# ATmega406 device description
Architecture: AVR8; Family: megaAVR
Registers are 8-bit, access not given, no defined reset value unless marked. A register's access mark holds for its fields unless they carry their own. Offsets are from the block's base; [hi:lo] are bit positions; {n}, {i} and the like mark numbered series; 'fields as' and 'values as' point back to an identical list.

## LOCKBIT — Lockbits
Instances: LOCKBIT 0 in lockbits
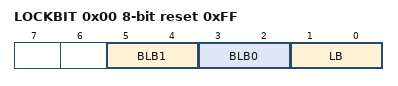
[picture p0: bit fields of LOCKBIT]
0x00 LOCKBIT reset 0xFF
  [5:4] BLB1 — Boot Loader Protection Mode
    0=LPM_SPM_DISABLE (LPM and SPM prohibited in Boot Section); 1=LPM_DISABLE (LPM prohibited in Boot Section); 2=SPM_DISABLE (SPM prohibited in Boot Section); 3=NO_LOCK (No lock on SPM and LPM in Boot Section)
  [3:2] BLB0 — Boot Loader Protection Mode
    0=LPM_SPM_DISABLE (LPM and SPM prohibited in Application Section); 1=LPM_DISABLE (LPM prohibited in Application Section); 2=SPM_DISABLE (SPM prohibited in Application Section); 3=NO_LOCK (No lock on SPM and LPM in Application Section)
  [1:0] LB — Memory Lock
    0=PROG_VER_DISABLED (Further programming and verification disabled); 2=PROG_DISABLED (Further programming disabled); 3=NO_LOCK (No memory lock features enabled)

## ADC — Analog-to-Digital Converter
Instances: ADC 0x00
0x78 VADC 16-bit bits used 11:0 — VADC Data Register Bytes
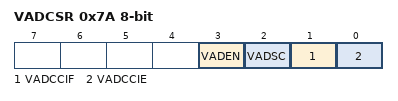
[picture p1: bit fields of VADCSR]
0x7A VADCSR — The VADC Control and Status register
  [3] VADEN — VADC Enable
  [2] VADSC — VADC Satrt Conversion
  [1] VADCCIF — VADC Conversion Complete Interrupt Flag
  [0] VADCCIE — VADC Conversion Complete Interrupt Enable
0x7C VADMUX — The VADC multiplexer Selection Register
  [3:0] VADMUX — Analog Channel and Gain Selection Bits

## EXINT — External Interrupts
Instances: EXINT 0x00
0x3B PCIFR — Pin Change Interrupt Flag Register
  [1:0] PCIF — Pin Change Interrupt Flags
0x3C EIFR — External Interrupt Flag Register
  [3:0] INTF — External Interrupt Flags
0x3D EIMSK — External Interrupt Mask Register
  [3:0] INT — External Interrupt Request 1 Enable
0x68 PCICR — Pin Change Interrupt Control Register
  [1:0] PCIE — Pin Change Interrupt Enables
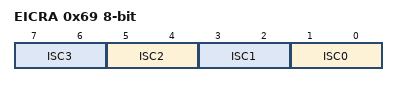
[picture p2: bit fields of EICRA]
0x69 EICRA — External Interrupt Control Register
  [all] fields
    0=Low Level of INTX; 1=Any Logical Change of INTX; 2=Falling Edge of INTX; 3=Rising Edge of INTX
  [2n+1:2n] ISC{n} (n=0..3) — External Interrupt Sense Control {n} Bits
0x6B PCMSK0 — Pin Change Enable Mask Register 0
0x6C PCMSK1 — Pin Change Enable Mask Register 1

## TC1 (TC16 module) — Timer/Counter, 16-bit
Instances: TC1 0x00
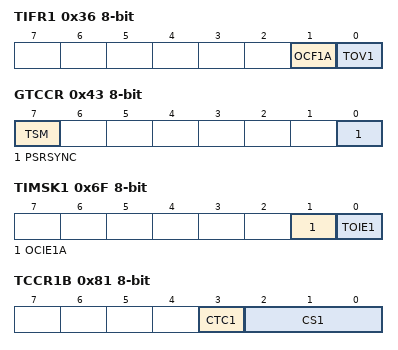
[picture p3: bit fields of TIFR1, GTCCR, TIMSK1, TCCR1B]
0x36 TIFR1 — Timer/Counter Interrupt Flag register
  [1] OCF1A — Timer/Counter1 Output Compare Flag A
  [0] TOV1 — Timer/Counter1 Overflow Flag
0x43 GTCCR — General Timer/Counter Control Register
  [7] TSM — Timer/Counter Synchronization Mode
  [0] PSRSYNC — Prescaler Reset
0x6F TIMSK1 — Timer/Counter Interrupt Mask Register
  [1] OCIE1A — Timer/Counter1 Output Compare Interrupt Enable
  [0] TOIE1 — Timer/Counter1 Overflow Interrupt Enable
0x81 TCCR1B — Timer/Counter1 Control Register B
  [3] CTC1 — Clear Timer/Counter on Compare Match
  [2:0] CS1 — Clock Select1 bits
    0=No Clock Source (Stopped); 1=Running, No Prescaling; 2=Running, CLK/8; 3=Running, CLK/32; 4=Running, CLK/64; 5=Running, CLK/128; 6=Running, CLK/256; 7=Running, CLK/1024
0x84 TCNT1 16-bit — Timer Counter 1 Bytes
0x88 OCR1AL — Output Compare Register 1A Low byte
0x89 OCR1AH — Output Compare Register 1A High byte

## WAKEUP_TIMER
Instances: WAKEUP_TIMER 0x00
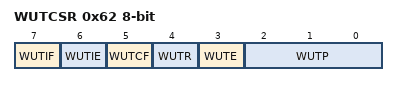
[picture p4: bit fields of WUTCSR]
0x62 WUTCSR — Wake-up Timer Control Register
  [7] WUTIF — Wake-up Timer Interrupt Flag
  [6] WUTIE — Wake-up Timer Interrupt Enable
  [5] WUTCF — Wake-up timer Calibration Flag
  [4] WUTR — Wake-up Timer Reset
  [3] WUTE — Wake-up Timer Enable
  [2:0] WUTP — Wake-up Timer Prescaler Bits
    0=4K(Slow RC) / 1K (32kHz); 1=8K(Slow RC) / 2K (32kHz); 2=16K(Slow RC) / 4K (32kHz); 3=32K(Slow RC) / 8K (32kHz); 4=64K(Slow RC) / 16K (32kHz); 5=128K(Slow RC) / 32K (32kHz); 6=256K(Slow RC) / 64K (32kHz); 7=512K(Slow RC) / 128K (32kHz)

## BATTERY_PROTECTION
Instances: BATTERY_PROTECTION 0x00
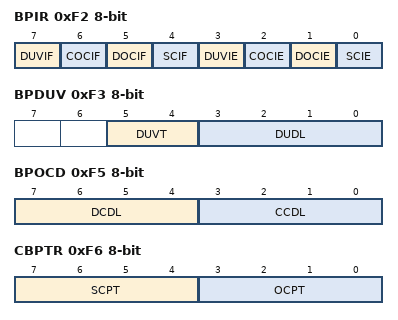
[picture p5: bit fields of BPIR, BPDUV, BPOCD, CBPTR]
0xF2 BPIR — Battery Protection Interrupt Register
  [7] DUVIF — Deep Under-voltage Early Warning Interrupt Flag
  [6] COCIF — Charge Over-current Protection Activated Interrupt Flag
  [5] DOCIF
  [4] SCIF
  [3] DUVIE — Deep Under-voltage Early Warning Interrupt Enable
  [2] COCIE
  [1] DOCIE
  [0] SCIE
0xF3 BPDUV — Battery Protection Deep Under Voltage Register
  [5:4] DUVT
    0=750ms; 1=1000ms; 2=1250ms; 3=1500ms
  [3:0] DUDL
    0=4.71V; 1=5.03V; 2=5.34V; 3=5.66V; 4=5.97V; 5=6.29V; 6=6.60V; 7=6.91V; 8=7.23V; 9=7.54V; 10=7.86V; 11=8.17V; 12=8.49V; 13=8.80V; 14=9.11V; 15=9.43V
0xF4 BPSCD — Battery Protection Short-Circuit Detection Level Register
  [3:0] SCDL
    0=0.100V; 1=0.110V; 2=0.120V; 3=0.130V; 4=0.140V; 5=0.160V; 6=0.180V; 7=0.200V; 8=0.220V; 9=0.240V; 10=0.260V; 11=0.280V; 12=0.320V; 13=0.360V; 14=0.400V; 15=0.440V
0xF5 BPOCD — Battery Protection OverCurrent Detection Level Register
  [7:4] DCDL
    0=0.050V; 1=0.055V; 2=0.060V; 3=0.065V; 4=0.070V; 5=0.080V; 6=0.090V; 7=0.100V; 8=0.110V; 9=0.120V; 10=0.130V; 11=0.140V; 12=0.160V; 13=0.180V; 14=0.200V; 15=0.220V
  [3:0] CCDL
    values as DCDL
0xF6 CBPTR — Current Battery Protection Timing Register
  [7:4] SCPT
    0=61 us; 1=122 us; 2=183 us; 3=244 us; 4=305 us; 5=366 us; 6=427 us; 7=488 us; 8=610 us; 9=732 us; 10=854 us; 11=976 us; 12=1098 us; 13=1220 us; 14=1342 us; 15=1464 us
  [3:0] OCPT
    0=1 ms; 1=2 ms; 2=4 ms; 3=6 ms; 4=8 ms; 5=10 ms; 6=12 ms; 7=14 ms; 8=16 ms; 9=18 ms; 10=20 ms; 11=22 ms; 12=24 ms; 13=26 ms; 14=28 ms; 15=30 ms
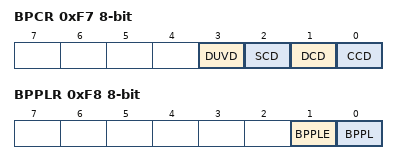
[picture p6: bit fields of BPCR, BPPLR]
0xF7 BPCR — Battery Protection Control Register
  [3] DUVD, [2] SCD, [1] DCD, [0] CCD
0xF8 BPPLR — Battery Protection Parameter Lock Register
  [1] BPPLE — Battery Protection Parameter Lock Enable
  [0] BPPL — Battery Protection Parameter Lock
